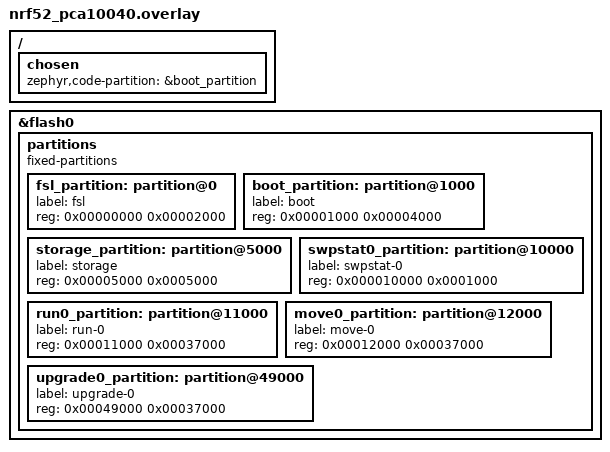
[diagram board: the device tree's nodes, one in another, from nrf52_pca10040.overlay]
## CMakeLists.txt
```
cmake_minimum_required(VERSION 3.13.1)
include($ENV{ZEPHYR_BASE}/cmake/app/boilerplate.cmake NO_POLICY_SCOPE)
project(bootloader)

FILE(GLOB app_sources src/*.c)

target_sources(app PRIVATE ${app_sources})
```

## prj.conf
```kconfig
CONFIG_HAS_FLASH_LOAD_OFFSET=y
CONFIG_USE_DT_CODE_PARTITION=y
CONFIG_TEXT_SECTION_OFFSET=0x200
CONFIG_ZB_EIGHT=y
CONFIG_ZB_EIGHT_IS_BOOTLOADER=y

CONFIG_FLASH=y
CONFIG_FLASH_PAGE_LAYOUT=n

CONFIG_I2C=n
CONFIG_WATCHDOG=n
CONFIG_GPIO=n
CONFIG_PINMUX=n
CONFIG_SPI=n
CONFIG_SYS_POWER_MANAGEMENT=n
CONFIG_BT=n

CONFIG_ARM=y
CONFIG_ARM_MPU=n

CONFIG_BOOT_BANNER=n
CONFIG_BOOT_DELAY=0
CONFIG_DEBUG=n

# Console
CONFIG_LOG=n
CONFIG_LOG_MINIMAL=n
CONFIG_CONSOLE=n
CONFIG_EARLY_CONSOLE=n
CONFIG_UART_CONSOLE=n
CONFIG_STDOUT_CONSOLE=n
CONFIG_PRINTK=n
CONFIG_SERIAL=n

CONFIG_MULTITHREADING=n
CONFIG_NUM_PREEMPT_PRIORITIES=0
CONFIG_SYS_CLOCK_EXISTS=n
```

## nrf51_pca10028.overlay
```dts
/*
 * Copyright (c) 2019 Laczen
 *
 * SPDX-License-Identifier: Apache-2.0
 */

/delete-node/ &boot_partition;
/delete-node/ &scratch_partition;
/delete-node/ &slot0_partition;
/delete-node/ &slot1_partition;
/delete-node/ &storage_partition;
/ {
	chosen {
		zephyr,code-partition = &boot_partition;
	};
};

&flash0 {
	/*
	 * For more information, see:
	 * http://docs.zephyrproject.org/latest/guides/dts/index.html#flash-partitions
	 */
	partitions {
		compatible = "fixed-partitions";
		#address-cells = <1>;
		#size-cells = <1>;

		fsl_partition: partition@0 {
			label = "fsl";
			reg = <0x00000000 0x00002000>;
		};
		boot_partition: partition@2000 {
			label = "boot";
			reg = <0x00002000 0x00004000>;
		};
		swpstat0_partition: partition@6000 {
			label = "swpstat-0";
			reg = <0x00006000 0x0000800>;
		};
		run0_partition: partition@6800 {
			label = "run-0";
			reg = <0x00006800 0x00010000>;
		};
		move0_partition: partition@6C00_0 {
			label = "move-0";
			reg = <0x00006C00 0x00010000>;
		};
		upgrade0_partition: partition@6C00_1 {
			label = "upgrade-0";
			reg = <0x00006C00 0x00010000>;
		};
	};
};
```

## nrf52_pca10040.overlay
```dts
/*
 * Copyright (c) 2019 Laczen
 *
 * SPDX-License-Identifier: Apache-2.0
 */

/delete-node/ &boot_partition;
/delete-node/ &scratch_partition;
/delete-node/ &slot0_partition;
/delete-node/ &slot1_partition;
/delete-node/ &storage_partition;

/ {
	chosen {
		zephyr,code-partition = &boot_partition;
	};
};

&flash0 {
	/*
	 * For more information, see:
	 * http://docs.zephyrproject.org/latest/guides/dts/index.html#flash-partitions
	 */
	partitions {
		compatible = "fixed-partitions";
		#address-cells = <1>;
		#size-cells = <1>;

		fsl_partition: partition@0 {
			label = "fsl";
			reg = <0x00000000 0x00002000>;
		};
		boot_partition: partition@1000 {
			label = "boot";
			reg = <0x00001000 0x00004000>;
		};
		storage_partition: partition@5000 {
			label = "storage";
			reg = <0x00005000 0x0005000>;
		};
		swpstat0_partition: partition@10000 {
			label = "swpstat-0";
			reg = <0x000010000 0x0001000>;
		};
		run0_partition: partition@11000 {
			label = "run-0";
			reg = <0x00011000 0x00037000>;
		};
		move0_partition: partition@12000 {
			label = "move-0";
			reg = <0x00012000 0x00037000>;
		};
		upgrade0_partition: partition@49000 {
			label = "upgrade-0";
			reg = <0x00049000 0x00037000>;
		};
	};
};
```

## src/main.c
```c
/*
 * Copyright (c) 2019 LaczenJMS.
 *
 * SPDX-License-Identifier: Apache-2.0
 */

#include <zephyr.h>
#include <zb8/zb8_move.h>
#include <zb8/zb8_fsl.h>

#include <logging/log.h>
LOG_MODULE_REGISTER(main);

void main(void)
{
	int cnt;

	cnt = zb_slt_area_cnt();

	/* Start or continue swap */
	while ((cnt--) > 0) {
		(void)zb_img_swap(cnt);
	}

	/* Boot image in run-0 slot or restart fsl */
	zb_fsl_boot(RUN_SLT);
	zb_fsl_boot(FSL_SLT);
}
```

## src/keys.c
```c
/* Autogenerated by zb8tool.py, do not edit. */
const unsigned char ec256_boot_pri_key[] = {
	0xf6, 0x96, 0xe9, 0x4f, 0xa5, 0x5d, 0xd1, 0xda,
	0x2b, 0x77, 0x44, 0x8d, 0x5b, 0x0a, 0x25, 0x3d,
	0x6b, 0x12, 0x59, 0xe9, 0x7f, 0x9f, 0x75, 0x18,
	0x9c, 0xa3, 0xbd, 0x2c, 0x3a, 0x17, 0x5d, 0x83,
};
const unsigned int ec256_boot_pri_key_len = 32;

const unsigned char ec256_root_pub_key[] = {
	0x2e, 0x8d, 0xef, 0xb8, 0x12, 0xf7, 0x2d, 0x71,
	0x2f, 0xdf, 0xc5, 0xa5, 0x2c, 0x08, 0x5d, 0xc8,
	0xd5, 0x7d, 0x8f, 0x5b, 0xa9, 0xa4, 0x93, 0xf3,
	0xe7, 0x9e, 0x37, 0x98, 0xef, 0xf8, 0xbd, 0x41,
	0x37, 0x94, 0x32, 0x79, 0xea, 0x3b, 0xdc, 0xd4,
	0x9a, 0xc9, 0xb0, 0x98, 0x06, 0x33, 0xee, 0x83,
	0xfd, 0x24, 0x81, 0xfe, 0x09, 0xfa, 0xd3, 0xde,
	0xda, 0xc0, 0x13, 0xd0, 0xad, 0x2b, 0x15, 0x1d,
};
const unsigned int ec256_root_pub_key_len = 64;
```
